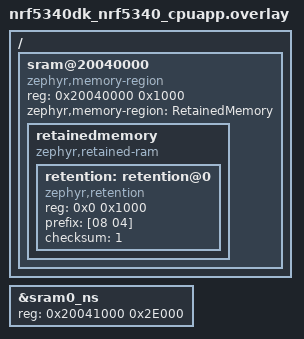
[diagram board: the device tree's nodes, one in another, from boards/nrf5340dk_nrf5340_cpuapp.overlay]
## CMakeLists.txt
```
# SPDX-License-Identifier: Apache-2.0

cmake_minimum_required(VERSION 3.20.0)
find_package(Zephyr REQUIRED HINTS $ENV{ZEPHYR_BASE})
project(task_sleep)

target_sources(app PRIVATE src/main.c)
```

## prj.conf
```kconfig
CONFIG_PM_DEVICE=y
CONFIG_SERIAL=n

# Enable logging over RTT
CONFIG_LOG=y

CONFIG_UART_CONSOLE=n
CONFIG_RTT_CONSOLE=y
CONFIG_USE_SEGGER_RTT=y

CONFIG_RETAINED_MEM=y
CONFIG_RETENTION=y
```

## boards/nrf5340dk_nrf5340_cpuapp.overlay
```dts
/ {
    sram@20040000 {
        compatible = "zephyr,memory-region";
        reg = <0x20040000 0x1000>;
        zephyr,memory-region = "RetainedMemory";
        status = "okay";

        retainedmemory {
            compatible = "zephyr,retained-ram";
            status = "okay";
            #address-cells = <1>;
            #size-cells = <1>;

            retention: retention@0 {
                compatible = "zephyr,retention";
                status = "okay";

                reg = <0x0 0x1000>;
                prefix = [08 04];
                checksum = <1>;
            };
        };
    };
};

&sram0_ns{
    reg = <0x20041000 0x2E000>;
};
```

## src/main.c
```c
/*
 * Copyright (c) 2024 Kelly Helmut Lord
 *
 * SPDX-License-Identifier: Apache-2.0
 */

#include <zephyr/kernel.h>
#include <zephyr/toolchain.h>
#include <zephyr/device.h>
#include <zephyr/retention/retention.h>

const struct device *retention = DEVICE_DT_GET(DT_NODELABEL(retention));

struct time {
	uint32_t hour;
	uint32_t minute;
	uint32_t centisecond;
};

struct k_timer reset_timer;
extern void reset_timer_handler(struct k_timer *timer_id) {
	sys_reboot(0);
}

int main(void)
{
	int ret;
	struct time current_time = {0};

	k_timer_init(&reset_timer, reset_timer_handler, NULL);
	k_timer_start(&reset_timer, K_SECONDS(10), K_NO_WAIT);

	if (!device_is_ready(retention)) {
		printk("Retention domain device is not ready\n");
		return -ENODEV;
	}


	if (retention_is_valid(retention) == 0) {
		printk("Retention data is not valid\n");
		ret = retention_clear(retention);
		if (ret) {
			printk("Failed to clear retention data\n");
			return ret;
		}
	}

	while (1) {

		ret = retention_read(retention, 0, &current_time, sizeof(current_time));
		if (ret) {
			printk("Failed to read retention data\n");
			return ret;
		}

		printk("Current time: %02d:%02d:%02d\n",
		       current_time.hour, current_time.minute, current_time.centisecond);

		current_time.centisecond++;

		ret = retention_write(retention, 0, &current_time, sizeof(current_time));	
		k_msleep(100);
	}
	return 0;
}
```
